AUTOSAR XML (schema 4.0)
standard types defined: float32, float64, sint16, sint32, sint8, uint16, uint32, uint8, void, boolean
package /ImplDataTypes
  6 x impl type, all with category=TYPE_REFERENCE, implementation-data-type=uint8, type-emitter=RTE:
    IoPositionSensorReadingType
    IoWeightSensorReadingType
    MultiStateBtnType
    SensorPositionType
    SensorWeightType
    StepMotorStepType
package /MappingSets
  data type mapping set MappingSet
package /PortInterfaces/ClientServer
  6 x client server interface:
    CsIf_IoGetSensorPosition
      operation IOGet_Height
        arg Io_position: type=IoPositionSensorReadingType, direction=OUT
      operation IOGet_Incline
        arg Io_position: type=IoPositionSensorReadingType, direction=OUT
      operation IOGet_Slide
        arg Io_position: type=IoPositionSensorReadingType, direction=OUT
    CsIf_IoGetSensorWeight
      operation IOGet_Weight
        arg Io_weight: type=IoWeightSensorReadingType, direction=OUT
    CsIf_IoSetMotor
      6 x operation:
        IOSetForward_Height
        IOSetForward_Incline
        IOSetForward_Slide
        IOSetReverse_Height
        IOSetReverse_Incline
        IOSetReverse_Slide
    CsIf_PositionSensor
      operation GetPosition_Height
        arg position: type=SensorPositionType, direction=OUT
      operation GetPosition_Incline
        arg position: type=SensorPositionType, direction=OUT
      operation GetPosition_Slide
        arg position: type=SensorPositionType, direction=OUT
    CsIf_StepMotor
      operation Opr_Move_HeightMotor
        arg Step: type=StepMotorStepType, direction=IN
      operation Opr_Move_InclineMotor
        arg Step: type=StepMotorStepType, direction=IN
      operation Opr_Move_SlideMotor
        arg Step: type=StepMotorStepType, direction=IN
    CsIf_WeightSensor
      operation GetWeight
        arg weight: type=SensorWeightType, direction=OUT
package /PortInterfaces/SenderReceiver
  sender receiver interface SrIf_SeatCtrlBtns
    data HeightBtnState: type=MultiStateBtnType
    data InclineBtnState: type=MultiStateBtnType
    data SlideBtnState: type=MultiStateBtnType
  sender receiver interface SrIf_SeatCtrlData
    data Height: type=uint8
    data Incline: type=uint8
    data Slide: type=uint8
package /SoftwareComponents
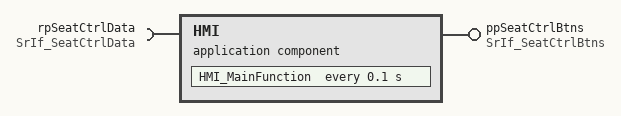
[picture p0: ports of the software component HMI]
  application sw component type HMI
    provide port ppSeatCtrlBtns: provided-interface=SrIf_SeatCtrlBtns
    require port rpSeatCtrlData: required-interface=SrIf_SeatCtrlData
    behavior Ibhv_HMI: data-type-mapping=MappingSet, handle-termination-and-restart=NO-SUPPORT
      timing event TE_HMI_MainFunction_100ms: start-on-event=HMI_MainFunction, period=0.1
      runnable HMI_MainFunction
        data-receive-point-by-arguments:
          access DRP_rpSeatCtrlData_Height: accessed-variable=rpSeatCtrlData.Height
          access DRP_rpSeatCtrlData_Incline: accessed-variable=rpSeatCtrlData.Incline
          access DRP_rpSeatCtrlData_Slide: accessed-variable=rpSeatCtrlData.Slide
        data-send-points:
          access DSP_ppSeatCtrlBtns_HeightBtnState: accessed-variable=ppSeatCtrlBtns.HeightBtnState
          access DSP_ppSeatCtrlBtns_InclineBtnState: accessed-variable=ppSeatCtrlBtns.InclineBtnState
          access DSP_ppSeatCtrlBtns_SlideBtnState: accessed-variable=ppSeatCtrlBtns.SlideBtnState
  5 x swc implementation, all with programming-language=C, sw-version=1.0.0, vendor-id=255:
    Impl_HMI: behavior=Ibhv_HMI
      code-descriptors:
        code Code: artifact-descriptors=autosar-engineering-object={short-label=SWC.c, category=SWSRC}
      resource consumption ResourceConsumption
    Impl_IoHwAbs: behavior=Ibhv_IoHwAbs
      code-descriptors:
        code Code: artifact-descriptors=autosar-engineering-object={short-label=SWC.c, category=SWSRC}
      resource consumption ResourceConsumption
    Impl_MotorCtrl: behavior=Ibhv_MotorCtrl
      code-descriptors:
        code Code: artifact-descriptors=autosar-engineering-object={short-label=SWC.c, category=SWSRC}
      resource consumption ResourceConsumption
    Impl_SeatManager: behavior=Ibhv_SeatManager
      code-descriptors:
        code Code: artifact-descriptors=autosar-engineering-object={short-label=SWC.c, category=SWSRC}
      resource consumption ResourceConsumption
    Impl_Sensors: behavior=Ibhv_Sensors
      code-descriptors:
        code Code: artifact-descriptors=autosar-engineering-object={short-label=SWC.c, category=SWSRC}
      resource consumption ResourceConsumption
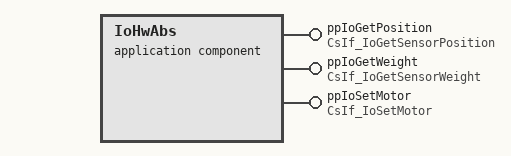
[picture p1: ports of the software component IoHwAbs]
  application sw component type IoHwAbs
    provide port ppIoGetPosition: provided-interface=CsIf_IoGetSensorPosition
    provide port ppIoGetWeight: provided-interface=CsIf_IoGetSensorWeight
    provide port ppIoSetMotor: provided-interface=CsIf_IoSetMotor
    behavior Ibhv_IoHwAbs: data-type-mapping=MappingSet, handle-termination-and-restart=NO-SUPPORT
      10 x operation invoked event:
        OIE_ppIoGetPosition_IOGet_Height: start-on-event=IoHwAbs_ECUGet_Height, operation=ppIoGetPosition.IOGet_Height
        OIE_ppIoGetPosition_IOGet_Incline: start-on-event=IoHwAbs_ECUGet_Incline, operation=ppIoGetPosition.IOGet_Incline
        OIE_ppIoGetPosition_IOGet_Slide: start-on-event=IoHwAbs_ECUGet_Slide, operation=ppIoGetPosition.IOGet_Slide
        OIE_ppIoGetWeight_IOGet_Weight: start-on-event=IoHwAbs_ECUGet_Weight, operation=ppIoGetWeight.IOGet_Weight
        OIE_ppIoSetMotor_IOSetForward_Height: start-on-event=IoHwAbs_ECUSetForward_Height, operation=ppIoSetMotor.IOSetForward_Height
        OIE_ppIoSetMotor_IOSetForward_Incline: start-on-event=IoHwAbs_ECUSetForward_Incline, operation=ppIoSetMotor.IOSetForward_Incline
        OIE_ppIoSetMotor_IOSetForward_Slide: start-on-event=IoHwAbs_ECUSetForward_Slide, operation=ppIoSetMotor.IOSetForward_Slide
        OIE_ppIoSetMotor_IOSetReverse_Height: start-on-event=IoHwAbs_ECUSetReverse_Height, operation=ppIoSetMotor.IOSetReverse_Height
        OIE_ppIoSetMotor_IOSetReverse_Incline: start-on-event=IoHwAbs_ECUSetReverse_Incline, operation=ppIoSetMotor.IOSetReverse_Incline
        OIE_ppIoSetMotor_IOSetReverse_Slide: start-on-event=IoHwAbs_ECUSetReverse_Slide, operation=ppIoSetMotor.IOSetReverse_Slide
      10 x runnable:
        IoHwAbs_ECUGet_Height
        IoHwAbs_ECUGet_Incline
        IoHwAbs_ECUGet_Slide
        IoHwAbs_ECUGet_Weight
        IoHwAbs_ECUSetForward_Height
        IoHwAbs_ECUSetForward_Incline
        IoHwAbs_ECUSetForward_Slide
        IoHwAbs_ECUSetReverse_Height
        IoHwAbs_ECUSetReverse_Incline
        IoHwAbs_ECUSetReverse_Slide
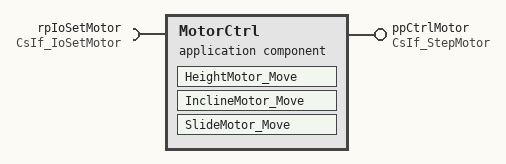
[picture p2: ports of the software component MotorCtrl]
  application sw component type MotorCtrl
    provide port ppCtrlMotor: provided-interface=CsIf_StepMotor
    require port rpIoSetMotor: required-interface=CsIf_IoSetMotor
    behavior Ibhv_MotorCtrl: data-type-mapping=MappingSet, handle-termination-and-restart=NO-SUPPORT
      operation invoked event OIE_ppCtrlMotor_Opr_Move_HeightMotor: start-on-event=HeightMotor_Move, operation=ppCtrlMotor.Opr_Move_HeightMotor
      operation invoked event OIE_ppCtrlMotor_Opr_Move_InclineMotor: start-on-event=InclineMotor_Move, operation=ppCtrlMotor.Opr_Move_InclineMotor
      operation invoked event OIE_ppCtrlMotor_Opr_Move_SlideMotor: start-on-event=SlideMotor_Move, operation=ppCtrlMotor.Opr_Move_SlideMotor
      runnable HeightMotor_Move
        sync call SCP_rpIoSetMotor_IOSetForward_Height: operation=rpIoSetMotor.IOSetForward_Height, timeout=0.0
        sync call SCP_rpIoSetMotor_IOSetReverse_Height: operation=rpIoSetMotor.IOSetReverse_Height, timeout=0.0
      runnable InclineMotor_Move
        sync call SCP_rpIoSetMotor_IOSetForward_Incline: operation=rpIoSetMotor.IOSetForward_Incline, timeout=0.0
        sync call SCP_rpIoSetMotor_IOSetReverse_Incline: operation=rpIoSetMotor.IOSetReverse_Incline, timeout=0.0
      runnable SlideMotor_Move
        sync call SCP_rpIoSetMotor_IOSetForward_Slide: operation=rpIoSetMotor.IOSetForward_Slide, timeout=0.0
        sync call SCP_rpIoSetMotor_IOSetReverse_Slide: operation=rpIoSetMotor.IOSetReverse_Slide, timeout=0.0
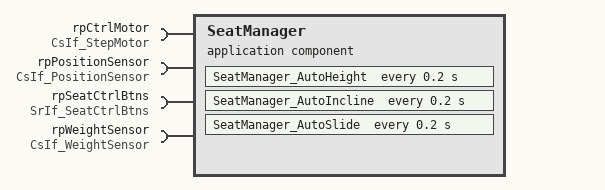
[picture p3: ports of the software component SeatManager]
  application sw component type SeatManager
    4 x require port:
      rpCtrlMotor: required-interface=CsIf_StepMotor
      rpPositionSensor: required-interface=CsIf_PositionSensor
      rpSeatCtrlBtns: required-interface=SrIf_SeatCtrlBtns
      rpWeightSensor: required-interface=CsIf_WeightSensor
    behavior Ibhv_SeatManager: data-type-mapping=MappingSet, handle-termination-and-restart=NO-SUPPORT
      data received event DRE_rpSeatCtrlBtns_HeightBtnState: start-on-event=SeatManager_SetHeight, data=rpSeatCtrlBtns.HeightBtnState
      data received event DRE_rpSeatCtrlBtns_InclineBtnState: start-on-event=SeatManager_SetIncline, data=rpSeatCtrlBtns.InclineBtnState
      data received event DRE_rpSeatCtrlBtns_SlideBtnState: start-on-event=SeatManager_SetSlide, data=rpSeatCtrlBtns.SlideBtnState
      timing event TE_SeatManager_AutoHeight_200ms: start-on-event=SeatManager_AutoHeight, period=0.2
      timing event TE_SeatManager_AutoIncline_200ms: start-on-event=SeatManager_AutoIncline, period=0.2
      timing event TE_SeatManager_AutoSlide_200ms: start-on-event=SeatManager_AutoSlide, period=0.2
      6 x runnable:
        SeatManager_AutoHeight
          sync call SCP_rpCtrlMotor_Opr_Move_HeightMotor: operation=rpCtrlMotor.Opr_Move_HeightMotor, timeout=0.0
          sync call SCP_rpPositionSensor_GetPosition_Height: operation=rpPositionSensor.GetPosition_Height, timeout=0.0
          sync call SCP_rpWeightSensor_GetWeight: operation=rpWeightSensor.GetWeight, timeout=0.0
        SeatManager_AutoIncline
          sync call SCP_rpCtrlMotor_Opr_Move_InclineMotor: operation=rpCtrlMotor.Opr_Move_InclineMotor, timeout=0.0
          sync call SCP_rpPositionSensor_GetPosition_Incline: operation=rpPositionSensor.GetPosition_Incline, timeout=0.0
          sync call SCP_rpWeightSensor_GetWeight: operation=rpWeightSensor.GetWeight, timeout=0.0
        SeatManager_AutoSlide
          sync call SCP_rpCtrlMotor_Opr_Move_SlideMotor: operation=rpCtrlMotor.Opr_Move_SlideMotor, timeout=0.0
          sync call SCP_rpPositionSensor_GetPosition_Slide: operation=rpPositionSensor.GetPosition_Slide, timeout=0.0
          sync call SCP_rpWeightSensor_GetWeight: operation=rpWeightSensor.GetWeight, timeout=0.0
        SeatManager_SetHeight
          data-receive-point-by-arguments:
            access DRP_rpSeatCtrlBtns_HeightBtnState: accessed-variable=rpSeatCtrlBtns.HeightBtnState
          sync call SCP_rpCtrlMotor_Opr_Move_HeightMotor: operation=rpCtrlMotor.Opr_Move_HeightMotor, timeout=0.0
        SeatManager_SetIncline
          data-receive-point-by-arguments:
            access DRP_rpSeatCtrlBtns_InclineBtnState: accessed-variable=rpSeatCtrlBtns.InclineBtnState
          sync call SCP_rpCtrlMotor_Opr_Move_InclineMotor: operation=rpCtrlMotor.Opr_Move_InclineMotor, timeout=0.0
        SeatManager_SetSlide
          data-receive-point-by-arguments:
            access DRP_rpSeatCtrlBtns_SlideBtnState: accessed-variable=rpSeatCtrlBtns.SlideBtnState
          sync call SCP_rpCtrlMotor_Opr_Move_SlideMotor: operation=rpCtrlMotor.Opr_Move_SlideMotor, timeout=0.0
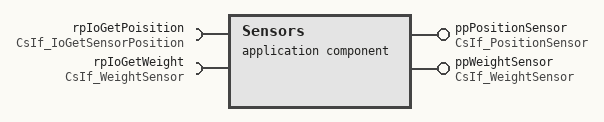
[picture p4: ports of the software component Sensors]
  application sw component type Sensors
    provide port ppPositionSensor: provided-interface=CsIf_PositionSensor
    provide port ppWeightSensor: provided-interface=CsIf_WeightSensor
    require port rpIoGetPoisition: required-interface=CsIf_IoGetSensorPosition
    require port rpIoGetWeight: required-interface=CsIf_WeightSensor
    behavior Ibhv_Sensors: data-type-mapping=MappingSet, handle-termination-and-restart=NO-SUPPORT
      4 x operation invoked event:
        OIE_ppPositionSensor_GetPosition_Height: start-on-event=HeightSensor_GetPosition, operation=ppPositionSensor.GetPosition_Height
        OIE_ppPositionSensor_GetPosition_Incline: start-on-event=InclineSensor_GetPosition, operation=ppPositionSensor.GetPosition_Incline
        OIE_ppPositionSensor_GetPosition_Slide: start-on-event=SlideSensor_GetPosition, operation=ppPositionSensor.GetPosition_Slide
        OIE_ppWeightSensor_GetWeight: start-on-event=WeightSensor_GetWeight, operation=ppWeightSensor.GetWeight
      4 x runnable:
        HeightSensor_GetPosition
          sync call SCP_rpIoGetPoisition_IOGet_Height: operation=rpIoGetPoisition.IOGet_Height, timeout=0.0
        InclineSensor_GetPosition
          sync call SCP_rpIoGetPoisition_IOGet_Incline: operation=rpIoGetPoisition.IOGet_Incline, timeout=0.0
        SlideSensor_GetPosition
          sync call SCP_rpIoGetPoisition_IOGet_Slide: operation=rpIoGetPoisition.IOGet_Slide, timeout=0.0
        WeightSensor_GetWeight
          sync call SCP_rpIoGetWeight_GetWeight: operation=rpIoGetWeight.GetWeight, timeout=0.0
package /Compositions
  composition sw component type TestApp1Composition
    5 x component:
      HMI: type=HMI
      IoHwAbs: type=IoHwAbs
      MotorCtrl: type=MotorCtrl
      SeatManager: type=SeatManager
      Sensors: type=Sensors
    connect HMI.ppSeatCtrlBtns -> SeatManager.rpSeatCtrlBtns
    connect IoHwAbs.ppIoGetPosition -> Sensors.rpIoGetPoisition
    connect IoHwAbs.ppIoGetPosition -> Sensors.rpIoGetWeight
    connect IoHwAbs.ppIoSetMotor -> MotorCtrl.rpIoSetMotor
    connect MotorCtrl.ppCtrlMotor -> SeatManager.rpCtrlMotor
    connect Sensors.ppPositionSensor -> SeatManager.rpPositionSensor
    connect Sensors.ppWeightSensor -> SeatManager.rpWeightSensor
